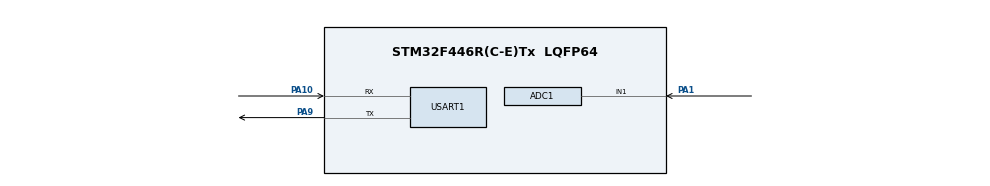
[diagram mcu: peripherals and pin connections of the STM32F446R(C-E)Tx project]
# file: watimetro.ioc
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ADC1.Channel-0\#ChannelRegularConversion=ADC_CHANNEL_1
ADC1.ContinuousConvMode=DISABLE
ADC1.DMAAccessMode=ADC_DMAACCESSMODE_2
ADC1.DMAContinuousRequests=ENABLE
ADC1.DiscontinuousConvMode=DISABLE
ADC1.ExternalTrigConv=ADC_EXTERNALTRIGCONV_T2_TRGO
ADC1.InjNumberOfConversion=0
ADC1.Mode=ADC_TRIPLEMODE_INTERL
ADC1.NbrOfConversionFlag=1
ADC1.ScanConvMode=DISABLE
ADC1.master=1
ADC2.Channel-1\#ChannelRegularConversion=ADC_CHANNEL_1
ADC2.DMAAccessMode=ADC_DMAACCESSMODE_2
ADC2.InjNumberOfConversion=0
ADC2.Mode=ADC_TRIPLEMODE_INTERL
ADC2.NbrOfConversionFlag=1
ADC2.Rank-1\#ChannelRegularConversion=1
ADC2.SamplingTime-1\#ChannelRegularConversion=ADC_SAMPLETIME_3CYCLES
ADC3.Channel-0\#ChannelRegularConversion=ADC_CHANNEL_1
ADC3.DMAAccessMode=ADC_DMAACCESSMODE_2
ADC3.EnableAnalogWatchDog=true
ADC3.Mode=ADC_TRIPLEMODE_INTERL
ADC3.NbrOfConversionFlag=1
ADC3.Rank-0\#ChannelRegularConversion=1
ADC3.SamplingTime-0\#ChannelRegularConversion=ADC_SAMPLETIME_3CYCLES
ADC3.ScanConvMode=DISABLE
ADC3.WatchdogChannel=ADC_CHANNEL_1
Dma.ADC1.0.Direction=DMA_PERIPH_TO_MEMORY
Dma.ADC1.0.FIFOMode=DMA_FIFOMODE_DISABLE
Dma.ADC1.0.Instance=DMA2_Stream0
Dma.ADC1.0.MemDataAlignment=DMA_MDATAALIGN_WORD
Dma.ADC1.0.MemInc=DMA_MINC_ENABLE
Dma.ADC1.0.Mode=DMA_CIRCULAR
Dma.ADC1.0.PeriphDataAlignment=DMA_PDATAALIGN_WORD
Dma.ADC1.0.PeriphInc=DMA_PINC_DISABLE
Dma.ADC1.0.Priority=DMA_PRIORITY_LOW
Dma.Request0=ADC1
FREERTOS.BinarySemaphores01=DmaPronto,Dynamic,NULL,Available
FREERTOS.Tasks01=defaultTask,24,128,StartDefaultTask,Default,NULL,Dynamic,NULL,NULL;aquisao,24,128,LerADC,Default,NULL,Dynamic,NULL,NULL
FREERTOS.configENABLE_FPU=1
Mcu.Family=STM32F4
Mcu.Name=STM32F446R(C-E)Tx
Mcu.Package=LQFP64
NVIC.ADC_IRQn=true\:5\:0\:false\:false\:true\:true\:true\:true\:true
NVIC.DMA2_Stream0_IRQn=true\:5\:0\:false\:false\:true\:true\:false\:true\:true
NVIC.PriorityGroup=NVIC_PRIORITYGROUP_4
NVIC.TIM1_UP_TIM10_IRQn=true\:15\:0\:false\:false\:true\:false\:false\:true\:true
NVIC.TimeBase=TIM1_UP_TIM10_IRQn
NVIC.TimeBaseIP=TIM1
PA1.Signal=ADCx_IN1
PA10.Mode=Asynchronous
PA10.Signal=USART1_RX
PA13.Mode=Trace_Asynchronous_SW
PA13.Signal=SYS_JTMS-SWDIO
PA14.Mode=Trace_Asynchronous_SW
PA14.Signal=SYS_JTCK-SWCLK
PA9.Mode=Asynchronous
PA9.Signal=USART1_TX
PB3.Mode=Trace_Asynchronous_SW
PB3.Signal=SYS_JTDO-SWO
PC14-OSC32_IN.Mode=LSE-External-Oscillator
PC14-OSC32_IN.Signal=RCC_OSC32_IN
PC15-OSC32_OUT.Mode=LSE-External-Oscillator
PC15-OSC32_OUT.Signal=RCC_OSC32_OUT
PH0-OSC_IN.Mode=HSE-External-Oscillator
PH0-OSC_IN.Signal=RCC_OSC_IN
PH1-OSC_OUT.Mode=HSE-External-Oscillator
PH1-OSC_OUT.Signal=RCC_OSC_OUT
ProjectManager.HeapSize=0x200
ProjectManager.StackSize=0x400
ProjectManager.TargetToolchain=STM32CubeIDE
RCC.CortexFreq_Value=16000000
RCC.USBFreq_Value=96000000
RCC.VCOOutputFreq_Value=192000000
SH.ADCx_IN1.0=ADC1_IN1,IN1
SH.ADCx_IN1.1=ADC2_IN1,IN1
SH.ADCx_IN1.2=ADC3_IN1,IN1
TIM2.Period=4999
TIM2.Prescaler=15999
TIM2.TIM_MasterOutputTrigger=TIM_TRGO_UPDATE
USART1.VirtualMode=VM_ASYNC
VP_FREERTOS_VS_CMSIS_V2.Mode=CMSIS_V2
VP_SYS_VS_tim1.Mode=TIM1
VP_TIM2_VS_ClockSourceINT.Mode=Internal
board=NUCLEO-F446RE

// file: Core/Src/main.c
/* USER CODE BEGIN Header */
/**
  ******************************************************************************
  * @file           : main.c
  * @brief          : Main program body
  ******************************************************************************
  * @attention
  *
  * Copyright (c) 2026 STMicroelectronics.
  * All rights reserved.
  *
  * This software is licensed under terms that can be found in the LICENSE file
  * in the root directory of this software component.
  * If no LICENSE file comes with this software, it is provided AS-IS.
  *
  ******************************************************************************
  */
/* USER CODE END Header */
#include "main.h"
#include "cmsis_os.h"

/* USER CODE BEGIN Includes */
#include "wattimetro.h"
/* USER CODE END Includes */

/* USER CODE BEGIN PD */
#define NUM_AMOSTRAS 100
/* USER CODE END PD */

ADC_HandleTypeDef hadc1;
ADC_HandleTypeDef hadc2;
ADC_HandleTypeDef hadc3;
DMA_HandleTypeDef hdma_adc1;

TIM_HandleTypeDef htim2;

UART_HandleTypeDef huart1;

/* Definitions for defaultTask */
osThreadId_t defaultTaskHandle;
const osThreadAttr_t defaultTask_attributes = {
  .name = "defaultTask",
  .stack_size = 128 * 4,
  .priority = (osPriority_t) osPriorityNormal,
};
/* Definitions for aquisao */
osThreadId_t aquisaoHandle;
const osThreadAttr_t aquisao_attributes = {
  .name = "aquisao",
  .stack_size = 128 * 4,
  .priority = (osPriority_t) osPriorityNormal,
};
/* Definitions for DmaPronto */
osSemaphoreId_t DmaProntoHandle;
const osSemaphoreAttr_t DmaPronto_attributes = {
  .name = "DmaPronto"
};

void SystemClock_Config(void);
static void MX_GPIO_Init(void);
static void MX_DMA_Init(void);
static void MX_ADC1_Init(void);
static void MX_ADC2_Init(void);
static void MX_ADC3_Init(void);
static void MX_USART1_UART_Init(void);
static void MX_TIM2_Init(void);
void StartDefaultTask(void *argument);
void LerADC(void *argument);

/* USER CODE BEGIN PFP */
// Vetor de 32 bits: armazena V
uint32_t buffer_dma[NUM_AMOSTRAS / 2];
uint16_t tensao_grafico; //  VARIAVEL GLOBAL PARA O GRAFICO
/* USER CODE END PFP */

int main(void)
{

  /* MCU Configuration--------------------------------------------------------*/

  /* Reset of all peripherals, Initializes the Flash interface and the Systick. */
  HAL_Init();

  /* Configure the system clock */
  SystemClock_Config();

  /* Initialize all configured peripherals */
  MX_GPIO_Init();
  MX_DMA_Init();
  MX_ADC1_Init();
  MX_ADC2_Init();
  MX_ADC3_Init();
  MX_USART1_UART_Init();
  MX_TIM2_Init();
  /* USER CODE BEGIN 2 */

  HAL_ADC_Start(&hadc2);
  HAL_ADC_Start(&hadc3);
  HAL_ADCEx_MultiModeStart_DMA(&hadc1, buffer_dma, NUM_AMOSTRAS/2);
  HAL_TIM_Base_Start(&htim2);

  /* USER CODE END 2 */

  /* Init scheduler */
  osKernelInitialize();

  /* Create the semaphores(s) */
  /* creation of DmaPronto */
  DmaProntoHandle = osSemaphoreNew(1, 1, &DmaPronto_attributes);

  /* Create the thread(s) */
  /* creation of defaultTask */
  defaultTaskHandle = osThreadNew(StartDefaultTask, NULL, &defaultTask_attributes);

  /* creation of aquisao */
  aquisaoHandle = osThreadNew(LerADC, NULL, &aquisao_attributes);

  /* Start scheduler */
  osKernelStart();

  /* We should never get here as control is now taken by the scheduler */

  /* Infinite loop */
  while (1)
  {

  }
}

void SystemClock_Config(void)
{
  RCC_OscInitTypeDef RCC_OscInitStruct = {0};
  RCC_ClkInitTypeDef RCC_ClkInitStruct = {0};

  /** Configure the main internal regulator output voltage
  */
  __HAL_RCC_PWR_CLK_ENABLE();
  __HAL_PWR_VOLTAGESCALING_CONFIG(PWR_REGULATOR_VOLTAGE_SCALE3);

  /** Initializes the RCC Oscillators according to the specified parameters
  * in the RCC_OscInitTypeDef structure.
  */
  RCC_OscInitStruct.OscillatorType = RCC_OSCILLATORTYPE_HSI;
  RCC_OscInitStruct.HSIState = RCC_HSI_ON;
  RCC_OscInitStruct.HSICalibrationValue = RCC_HSICALIBRATION_DEFAULT;
  RCC_OscInitStruct.PLL.PLLState = RCC_PLL_NONE;
  if (HAL_RCC_OscConfig(&RCC_OscInitStruct) != HAL_OK)
  {
    Error_Handler();
  }

  /** Initializes the CPU, AHB and APB buses clocks
  */
  RCC_ClkInitStruct.ClockType = RCC_CLOCKTYPE_HCLK|RCC_CLOCKTYPE_SYSCLK
                              |RCC_CLOCKTYPE_PCLK1|RCC_CLOCKTYPE_PCLK2;
  RCC_ClkInitStruct.SYSCLKSource = RCC_SYSCLKSOURCE_HSI;
  RCC_ClkInitStruct.AHBCLKDivider = RCC_SYSCLK_DIV1;
  RCC_ClkInitStruct.APB1CLKDivider = RCC_HCLK_DIV1;
  RCC_ClkInitStruct.APB2CLKDivider = RCC_HCLK_DIV1;

  if (HAL_RCC_ClockConfig(&RCC_ClkInitStruct, FLASH_LATENCY_0) != HAL_OK)
  {
    Error_Handler();
  }
}

static void MX_ADC1_Init(void)
{

  ADC_MultiModeTypeDef multimode = {0};
  ADC_ChannelConfTypeDef sConfig = {0};

  /** Configure the global features of the ADC (Clock, Resolution, Data Alignment and number of conversion)
  */
  hadc1.Instance = ADC1;
  hadc1.Init.ClockPrescaler = ADC_CLOCK_SYNC_PCLK_DIV2;
  hadc1.Init.Resolution = ADC_RESOLUTION_12B;
  hadc1.Init.ScanConvMode = DISABLE;
  hadc1.Init.ContinuousConvMode = DISABLE;
  hadc1.Init.DiscontinuousConvMode = DISABLE;
  hadc1.Init.ExternalTrigConvEdge = ADC_EXTERNALTRIGCONVEDGE_RISING;
  hadc1.Init.ExternalTrigConv = ADC_EXTERNALTRIGCONV_T2_TRGO;
  hadc1.Init.DataAlign = ADC_DATAALIGN_RIGHT;
  hadc1.Init.NbrOfConversion = 1;
  hadc1.Init.DMAContinuousRequests = ENABLE;
  hadc1.Init.EOCSelection = ADC_EOC_SINGLE_CONV;
  if (HAL_ADC_Init(&hadc1) != HAL_OK)
  {
    Error_Handler();
  }

  /** Configure the ADC multi-mode
  */
  multimode.Mode = ADC_TRIPLEMODE_INTERL;
  multimode.DMAAccessMode = ADC_DMAACCESSMODE_2;
  multimode.TwoSamplingDelay = ADC_TWOSAMPLINGDELAY_5CYCLES;
  if (HAL_ADCEx_MultiModeConfigChannel(&hadc1, &multimode) != HAL_OK)
  {
    Error_Handler();
  }

  /** Configure for the selected ADC regular channel its corresponding rank in the sequencer and its sample time.
  */
  sConfig.Channel = ADC_CHANNEL_1;
  sConfig.Rank = 1;
  sConfig.SamplingTime = ADC_SAMPLETIME_3CYCLES;
  if (HAL_ADC_ConfigChannel(&hadc1, &sConfig) != HAL_OK)
  {
    Error_Handler();
  }

}

static void MX_ADC2_Init(void)
{

  ADC_ChannelConfTypeDef sConfig = {0};

  /** Configure the global features of the ADC (Clock, Resolution, Data Alignment and number of conversion)
  */
  hadc2.Instance = ADC2;
  hadc2.Init.ClockPrescaler = ADC_CLOCK_SYNC_PCLK_DIV2;
  hadc2.Init.Resolution = ADC_RESOLUTION_12B;
  hadc2.Init.ScanConvMode = DISABLE;
  hadc2.Init.ContinuousConvMode = DISABLE;
  hadc2.Init.DiscontinuousConvMode = DISABLE;
  hadc2.Init.DataAlign = ADC_DATAALIGN_RIGHT;
  hadc2.Init.NbrOfConversion = 1;
  hadc2.Init.DMAContinuousRequests = DISABLE;
  hadc2.Init.EOCSelection = ADC_EOC_SINGLE_CONV;
  if (HAL_ADC_Init(&hadc2) != HAL_OK)
  {
    Error_Handler();
  }

  /** Configure for the selected ADC regular channel its corresponding rank in the sequencer and its sample time.
  */
  sConfig.Channel = ADC_CHANNEL_1;
  sConfig.Rank = 1;
  sConfig.SamplingTime = ADC_SAMPLETIME_3CYCLES;
  if (HAL_ADC_ConfigChannel(&hadc2, &sConfig) != HAL_OK)
  {
    Error_Handler();
  }

}

static void MX_ADC3_Init(void)
{

  ADC_AnalogWDGConfTypeDef AnalogWDGConfig = {0};
  ADC_ChannelConfTypeDef sConfig = {0};

  /** Configure the global features of the ADC (Clock, Resolution, Data Alignment and number of conversion)
  */
  hadc3.Instance = ADC3;
  hadc3.Init.ClockPrescaler = ADC_CLOCK_SYNC_PCLK_DIV2;
  hadc3.Init.Resolution = ADC_RESOLUTION_12B;
  hadc3.Init.ScanConvMode = DISABLE;
  hadc3.Init.ContinuousConvMode = DISABLE;
  hadc3.Init.DiscontinuousConvMode = DISABLE;
  hadc3.Init.DataAlign = ADC_DATAALIGN_RIGHT;
  hadc3.Init.NbrOfConversion = 1;
  hadc3.Init.DMAContinuousRequests = DISABLE;
  hadc3.Init.EOCSelection = ADC_EOC_SINGLE_CONV;
  if (HAL_ADC_Init(&hadc3) != HAL_OK)
  {
    Error_Handler();
  }

  /** Configure the analog watchdog
  */
  AnalogWDGConfig.WatchdogMode = ADC_ANALOGWATCHDOG_SINGLE_REG;
  AnalogWDGConfig.HighThreshold = 0;
  AnalogWDGConfig.LowThreshold = 0;
  AnalogWDGConfig.Channel = ADC_CHANNEL_1;
  AnalogWDGConfig.ITMode = DISABLE;
  if (HAL_ADC_AnalogWDGConfig(&hadc3, &AnalogWDGConfig) != HAL_OK)
  {
    Error_Handler();
  }

  /** Configure for the selected ADC regular channel its corresponding rank in the sequencer and its sample time.
  */
  sConfig.Channel = ADC_CHANNEL_1;
  sConfig.Rank = 1;
  sConfig.SamplingTime = ADC_SAMPLETIME_3CYCLES;
  if (HAL_ADC_ConfigChannel(&hadc3, &sConfig) != HAL_OK)
  {
    Error_Handler();
  }

}

static void MX_TIM2_Init(void)
{

  TIM_ClockConfigTypeDef sClockSourceConfig = {0};
  TIM_MasterConfigTypeDef sMasterConfig = {0};

  htim2.Instance = TIM2;
  htim2.Init.Prescaler = 0;
  htim2.Init.CounterMode = TIM_COUNTERMODE_UP;
  htim2.Init.Period = 899;
  htim2.Init.ClockDivision = TIM_CLOCKDIVISION_DIV1;
  htim2.Init.AutoReloadPreload = TIM_AUTORELOAD_PRELOAD_DISABLE;
  if (HAL_TIM_Base_Init(&htim2) != HAL_OK)
  {
    Error_Handler();
  }
  sClockSourceConfig.ClockSource = TIM_CLOCKSOURCE_INTERNAL;
  if (HAL_TIM_ConfigClockSource(&htim2, &sClockSourceConfig) != HAL_OK)
  {
    Error_Handler();
  }
  sMasterConfig.MasterOutputTrigger = TIM_TRGO_UPDATE;
  sMasterConfig.MasterSlaveMode = TIM_MASTERSLAVEMODE_DISABLE;
  if (HAL_TIMEx_MasterConfigSynchronization(&htim2, &sMasterConfig) != HAL_OK)
  {
    Error_Handler();
  }

}

static void MX_USART1_UART_Init(void)
{

  huart1.Instance = USART1;
  huart1.Init.BaudRate = 115200;
  huart1.Init.WordLength = UART_WORDLENGTH_8B;
  huart1.Init.StopBits = UART_STOPBITS_1;
  huart1.Init.Parity = UART_PARITY_NONE;
  huart1.Init.Mode = UART_MODE_TX_RX;
  huart1.Init.HwFlowCtl = UART_HWCONTROL_NONE;
  huart1.Init.OverSampling = UART_OVERSAMPLING_16;
  if (HAL_UART_Init(&huart1) != HAL_OK)
  {
    Error_Handler();
  }

}

static void MX_DMA_Init(void)
{

  /* DMA controller clock enable */
  __HAL_RCC_DMA2_CLK_ENABLE();

  /* DMA interrupt init */
  /* DMA2_Stream0_IRQn interrupt configuration */
  HAL_NVIC_SetPriority(DMA2_Stream0_IRQn, 5, 0);
  HAL_NVIC_EnableIRQ(DMA2_Stream0_IRQn);

}

static void MX_GPIO_Init(void)
{

  /* GPIO Ports Clock Enable */
  __HAL_RCC_GPIOC_CLK_ENABLE();
  __HAL_RCC_GPIOH_CLK_ENABLE();
  __HAL_RCC_GPIOA_CLK_ENABLE();

}

/* USER CODE BEGIN 4 */
void HAL_ADC_ConvCpltCallback(ADC_HandleTypeDef* hadc) {
    if(hadc->Instance == ADC1) {
        osSemaphoreRelease(DmaProntoHandle);
    }
}

/* USER CODE END 4 */

void StartDefaultTask(void *argument)
{
  for(;;)
  {
    osDelay(1);
  }
}

void LerADC(void *argument)
{
  /* USER CODE BEGIN LerADC */
	// Limpa a "falsa" disponibilidade do semáforo antes de começar
	  osSemaphoreAcquire(DmaProntoHandle, 0);
  /* Infinite loop */
  for(;;)
  {
  // Aguarda o DMA ler as 100 amostras
	  if (osSemaphoreAcquire(DmaProntoHandle, osWaitForever) == osOK)
	  {
		  //  Le o buffer de 32 bits como se fosse um buffer linear de 16 bits
		  uint16_t *amostras_ordenadas = (uint16_t*) buffer_dma;
		  uint32_t soma_quadrados = 0;

		  for(int i = 0; i < NUM_AMOSTRAS; i++)
		  {
			// O indice [i] agora contem a leitura pura (0 a 4095),
			// perfeitamente sequenciada no tempo:
			// i=0 (ADC1), i=1 (ADC2), i=2 (ADC3), i=3 (ADC1 de novo), etc...

			uint16_t amostra_tensao = amostras_ordenadas[i];
			soma_quadrados += (uint32_t)(amostra_tensao * amostra_tensao);
		   tensao_grafico=amostra_tensao;

		  }
		  osDelay(1);
	  }
  }
  /* USER CODE END LerADC */
}

void HAL_TIM_PeriodElapsedCallback(TIM_HandleTypeDef *htim)
{
  if (htim->Instance == TIM1)
  {
    HAL_IncTick();
  }
}

void Error_Handler(void)
{
  __disable_irq();
  while (1)
  {
  }
}
